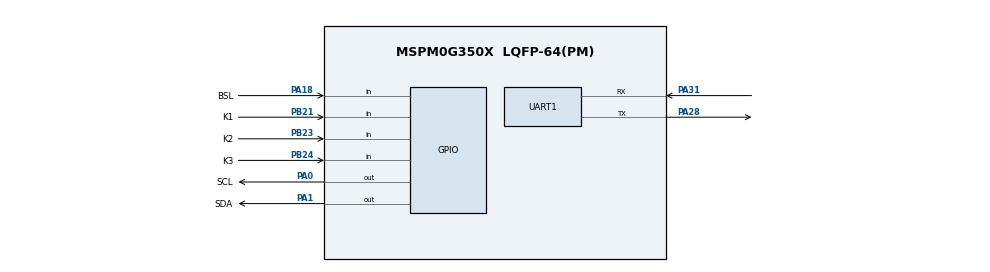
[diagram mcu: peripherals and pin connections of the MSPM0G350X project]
/**
 * @cliArgs --device "MSPM0G350X" --part "Default" --package "LQFP-64(PM)" --product "mspm0_sdk@2.01.00.03"
 * @versions {"tool":"1.21.0+3721"}
 */

/**
 * Import the modules used in this configuration.
 */
const GPIO    = scripting.addModule("/ti/driverlib/GPIO", {}, false);
const GPIO1   = GPIO.addInstance();
const GPIO2   = GPIO.addInstance();
const GPIO3   = GPIO.addInstance();
const GPIO4   = GPIO.addInstance();
const GPIO5   = GPIO.addInstance();
const PWM     = scripting.addModule("/ti/driverlib/PWM", {}, false);
const PWM1    = PWM.addInstance();
const QEI     = scripting.addModule("/ti/driverlib/QEI", {}, false);
const QEI1    = QEI.addInstance();
const SYSCTL  = scripting.addModule("/ti/driverlib/SYSCTL");
const SYSTICK = scripting.addModule("/ti/driverlib/SYSTICK");
const TIMER   = scripting.addModule("/ti/driverlib/TIMER", {}, false);
const TIMER1  = TIMER.addInstance();
const UART    = scripting.addModule("/ti/driverlib/UART", {}, false);
const UART1   = UART.addInstance();
const UART2   = UART.addInstance();

/**
 * Write custom configuration values to the imported modules.
 */
const gate7  = system.clockTree["MFCLKGATE"];
gate7.enable = true;

GPIO1.$name                              = "KEY";
GPIO1.port                               = "PORTB";
GPIO1.associatedPins.create(3);
GPIO1.associatedPins[0].internalResistor = "PULL_DOWN";
GPIO1.associatedPins[0].$name            = "K1";
GPIO1.associatedPins[0].assignedPin      = "21";
GPIO1.associatedPins[0].direction        = "INPUT";
GPIO1.associatedPins[0].interruptEn      = true;
GPIO1.associatedPins[0].polarity         = "RISE";
GPIO1.associatedPins[0].pin.$assign      = "PB21";
GPIO1.associatedPins[1].$name            = "K2";
GPIO1.associatedPins[1].direction        = "INPUT";
GPIO1.associatedPins[1].assignedPin      = "23";
GPIO1.associatedPins[1].pin.$assign      = "PB23";
GPIO1.associatedPins[2].$name            = "K3";
GPIO1.associatedPins[2].assignedPin      = "24";
GPIO1.associatedPins[2].direction        = "INPUT";
GPIO1.associatedPins[2].pin.$assign      = "PB24";

const Board = scripting.addModule("/ti/driverlib/Board", {}, false);

GPIO2.$name                          = "Motor";
GPIO2.port                           = "PORTA";
GPIO2.associatedPins.create(4);
GPIO2.associatedPins[0].initialValue = "SET";
GPIO2.associatedPins[0].assignedPin  = "14";
GPIO2.associatedPins[0].$name        = "AIN1";
GPIO2.associatedPins[1].$name        = "AIN2";
GPIO2.associatedPins[1].assignedPin  = "16";
GPIO2.associatedPins[2].$name        = "BIN1";
GPIO2.associatedPins[2].initialValue = "SET";
GPIO2.associatedPins[2].assignedPin  = "15";
GPIO2.associatedPins[3].$name        = "BIN2";
GPIO2.associatedPins[3].assignedPin  = "17";

GPIO3.port                          = "PORTA";
GPIO3.$name                         = "GPIO_EncoderA";
GPIO3.associatedPins.create(2);
GPIO3.associatedPins[0].direction   = "INPUT";
GPIO3.associatedPins[0].interruptEn = true;
GPIO3.associatedPins[0].polarity    = "RISE";
GPIO3.associatedPins[0].$name       = "PIN_8";
GPIO3.associatedPins[0].assignedPin = "8";
GPIO3.associatedPins[1].direction   = "INPUT";
GPIO3.associatedPins[1].interruptEn = true;
GPIO3.associatedPins[1].polarity    = "RISE";
GPIO3.associatedPins[1].$name       = "PIN_7";
GPIO3.associatedPins[1].assignedPin = "7";

GPIO4.$name                         = "sensor";
GPIO4.port                          = "PORTA";
GPIO4.associatedPins.create(5);
GPIO4.associatedPins[0].$name       = "PIN_3";
GPIO4.associatedPins[0].assignedPin = "3";
GPIO4.associatedPins[0].direction   = "INPUT";
GPIO4.associatedPins[1].$name       = "PIN_4";
GPIO4.associatedPins[1].assignedPin = "4";
GPIO4.associatedPins[1].direction   = "INPUT";
GPIO4.associatedPins[2].$name       = "PIN_5";
GPIO4.associatedPins[2].assignedPin = "5";
GPIO4.associatedPins[2].direction   = "INPUT";
GPIO4.associatedPins[3].$name       = "PIN_6";
GPIO4.associatedPins[3].assignedPin = "6";
GPIO4.associatedPins[3].direction   = "INPUT";
GPIO4.associatedPins[4].$name       = "BSL";
GPIO4.associatedPins[4].direction   = "INPUT";
GPIO4.associatedPins[4].assignedPin = "18";
GPIO4.associatedPins[4].pin.$assign = "PA18";

GPIO5.$name                          = "OLED";
GPIO5.port                           = "PORTA";
GPIO5.associatedPins.create(2);
GPIO5.associatedPins[0].$name        = "SCL";
GPIO5.associatedPins[0].initialValue = "SET";
GPIO5.associatedPins[0].ioStructure  = "OD";
GPIO5.associatedPins[0].assignedPin  = "0";
GPIO5.associatedPins[0].pin.$assign  = "PA0";
GPIO5.associatedPins[1].$name        = "SDA";
GPIO5.associatedPins[1].initialValue = "SET";
GPIO5.associatedPins[1].ioStructure  = "OD";
GPIO5.associatedPins[1].assignedPin  = "1";
GPIO5.associatedPins[1].pin.$assign  = "PA1";

PWM1.$name                              = "PWM_Motor";
PWM1.timerCount                         = 3200;
PWM1.timerStartTimer                    = true;
PWM1.pwmMode                            = "EDGE_ALIGN_UP";
PWM1.peripheral.$assign                 = "TIMG0";
PWM1.PWM_CHANNEL_0.$name                = "ti_driverlib_pwm_PWMTimerCC0";
PWM1.PWM_CHANNEL_1.$name                = "ti_driverlib_pwm_PWMTimerCC1";
PWM1.ccp0PinConfig.direction            = scripting.forceWrite("OUTPUT");
PWM1.ccp0PinConfig.hideOutputInversion  = scripting.forceWrite(false);
PWM1.ccp0PinConfig.onlyInternalResistor = scripting.forceWrite(false);
PWM1.ccp0PinConfig.passedPeripheralType = scripting.forceWrite("Digital");
PWM1.ccp0PinConfig.$name                = "ti_driverlib_gpio_GPIOPinGeneric4";
PWM1.ccp1PinConfig.direction            = scripting.forceWrite("OUTPUT");
PWM1.ccp1PinConfig.hideOutputInversion  = scripting.forceWrite(false);
PWM1.ccp1PinConfig.onlyInternalResistor = scripting.forceWrite(false);
PWM1.ccp1PinConfig.passedPeripheralType = scripting.forceWrite("Digital");
PWM1.ccp1PinConfig.$name                = "ti_driverlib_gpio_GPIOPinGeneric5";

QEI1.$name               = "QEI_0";
QEI1.ccp0PinConfig.$name = "ti_driverlib_gpio_GPIOPinGeneric6";
QEI1.ccp1PinConfig.$name = "ti_driverlib_gpio_GPIOPinGeneric7";

SYSCTL.forceDefaultClkConfig = true;
SYSCTL.clockTreeEn           = true;

SYSTICK.periodEnable      = true;
SYSTICK.interruptPriority = "0";
SYSTICK.systickEnable     = true;
SYSTICK.period            = 32;

TIMER1.$name              = "TIMER_Sensor";
TIMER1.timerMode          = "PERIODIC";
TIMER1.timerStartTimer    = true;
TIMER1.interrupts         = ["ZERO"];
TIMER1.timerClkSrc        = "LFCLK";
TIMER1.timerClkDiv        = 3;
TIMER1.timerPeriod        = "200 ms";
TIMER1.peripheral.$assign = "TIMG6";

UART1.$name                            = "UART_JY61P";
UART1.enabledInterrupts                = ["OVERRUN_ERROR","RX"];
UART1.peripheral.$assign               = "UART0";
UART1.peripheral.rxPin.$assign         = "PA31";
UART1.peripheral.txPin.$assign         = "PA28";
UART1.txPinConfig.direction            = scripting.forceWrite("OUTPUT");
UART1.txPinConfig.hideOutputInversion  = scripting.forceWrite(false);
UART1.txPinConfig.onlyInternalResistor = scripting.forceWrite(false);
UART1.txPinConfig.passedPeripheralType = scripting.forceWrite("Digital");
UART1.txPinConfig.$name                = "ti_driverlib_gpio_GPIOPinGeneric0";
UART1.rxPinConfig.hideOutputInversion  = scripting.forceWrite(false);
UART1.rxPinConfig.onlyInternalResistor = scripting.forceWrite(false);
UART1.rxPinConfig.passedPeripheralType = scripting.forceWrite("Digital");
UART1.rxPinConfig.$name                = "ti_driverlib_gpio_GPIOPinGeneric1";

UART2.$name             = "UART_1";
UART2.uartClkSrc        = "MFCLK";
UART2.txPinConfig.$name = "ti_driverlib_gpio_GPIOPinGeneric2";
UART2.rxPinConfig.$name = "ti_driverlib_gpio_GPIOPinGeneric3";

/**
 * Pinmux solution for unlocked pins/peripherals. This ensures that minor changes to the automatic solver in a future
 * version of the tool will not impact the pinmux you originally saw.  These lines can be completely deleted in order to
 * re-solve from scratch.
 */
Board.peripheral.$suggestSolution            = "DEBUGSS";
Board.peripheral.swclkPin.$suggestSolution   = "PA20";
Board.peripheral.swdioPin.$suggestSolution   = "PA19";
GPIO2.associatedPins[0].pin.$suggestSolution = "PA14";
GPIO2.associatedPins[1].pin.$suggestSolution = "PA16";
GPIO2.associatedPins[2].pin.$suggestSolution = "PA15";
GPIO2.associatedPins[3].pin.$suggestSolution = "PA17";
GPIO3.associatedPins[0].pin.$suggestSolution = "PA8";
GPIO3.associatedPins[1].pin.$suggestSolution = "PA7";
GPIO4.associatedPins[0].pin.$suggestSolution = "PA3";
GPIO4.associatedPins[1].pin.$suggestSolution = "PA4";
GPIO4.associatedPins[2].pin.$suggestSolution = "PA5";
GPIO4.associatedPins[3].pin.$suggestSolution = "PA6";
PWM1.peripheral.ccp0Pin.$suggestSolution     = "PA12";
PWM1.peripheral.ccp1Pin.$suggestSolution     = "PA13";
QEI1.peripheral.$suggestSolution             = "TIMG8";
QEI1.peripheral.ccp0Pin.$suggestSolution     = "PA21";
QEI1.peripheral.ccp1Pin.$suggestSolution     = "PA2";
UART2.peripheral.$suggestSolution            = "UART1";
UART2.peripheral.rxPin.$suggestSolution      = "PA9";
UART2.peripheral.txPin.$suggestSolution      = "PB4";
